# RL6842_IP_SVD register map
Vendor: Realtek
Registers are 32-bit, read-write, reset 0x0 unless marked. A register's access mark holds for its fields unless they carry their own. Offsets are from the block's base; [hi:lo] are bit positions; {n}, {i} and the like mark numbered series.

## page12
Base 0x40000000
{0x1200+0x10*i} REG_DDMA_CH{i}SA (i=0..5)
  [31:0] BIT_DDMACH{i}_SA — Source Address: the source SRAM address that DDMA will read from. This address bus support byte alignment.
{0x1204+0x10*i} REG_DDMA_CH{i}DA (i=0..5)
  [31:0] BIT_DDMACH{i}_DA — Destination Address: This address bus support byte alignment.
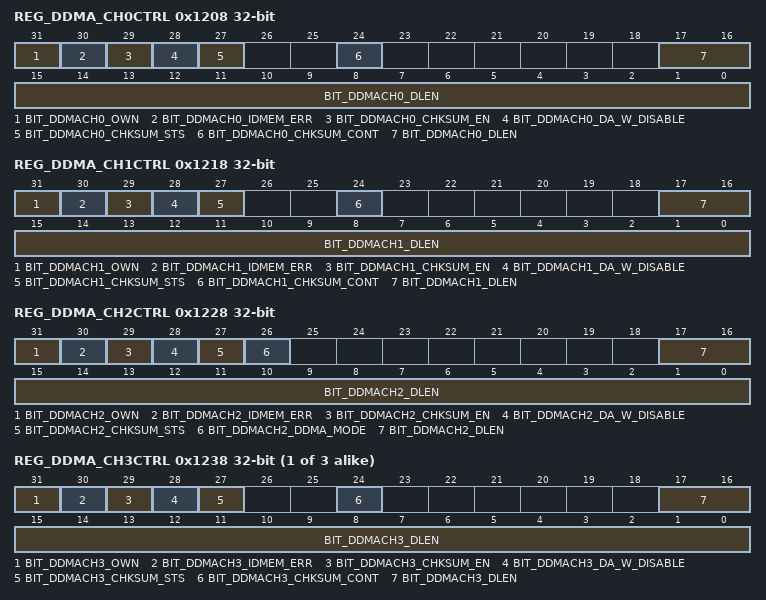
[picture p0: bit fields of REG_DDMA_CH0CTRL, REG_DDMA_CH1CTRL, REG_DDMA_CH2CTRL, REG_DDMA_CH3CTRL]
0x1208 REG_DDMA_CH0CTRL access per field
  [31] BIT_DDMACH0_OWN rw — Set '1' by firmware/driver to denote this DMA channel info is ready for DMA engine to begin DMA activity; after DMA complete, DMA engine will clear it to '0' to denote for firmware that this channel is standby again.
  [30] BIT_DDMACH0_IDMEM_ERR ro — 1: Ddma I/D MEM fail. Please check 0x80[0]=1 or DMEM protection is release 0: No error
  [29] BIT_DDMACH0_CHKSUM_EN rw — 16bits Exclusive OR checksum enable
  [28] BIT_DDMACH0_DA_W_DISABLE rw — DA write disable When DDMACH0_CHKSUM_EN=1, DDMACH0_DA_W_DISABLE = 1 means that DMA engine doesn't move pkt to destination but executes checksum only and report status to DDMACH0_CHKSUM_STS.
  [27] BIT_DDMACH0_CHKSUM_STS ro — 0: Exclusive OR checksum ok 1: Exclusive OR checksum fail
  [24] BIT_DDMACH0_CHKSUM_CONT rw — Set1, hw will continuously check sum in several ddma bursts
  [17:0] BIT_DDMACH0_DLEN rw — DMA Length: Length count served by DMA engine, unit in 1 bytes. The range is from 1 to 256K.
0x1218 REG_DDMA_CH1CTRL access per field
  [31] BIT_DDMACH1_OWN rw — Set '1' by firmware/driver to denote this DMA channel info is ready for DMA engine to begin DMA activity; after DMA complete, DMA engine will clear it to '0' to denote for firmware that this channel is standby again.
  [30] BIT_DDMACH1_IDMEM_ERR ro — 1: Ddma I/D MEM fail. Please check 0x80[0]=1 or DMEM protection is release 0: No error
  [29] BIT_DDMACH1_CHKSUM_EN rw — 16bits Exclusive OR checksum enable
  [28] BIT_DDMACH1_DA_W_DISABLE rw — DA write disable When DDMACH1_CHKSUM_EN=1, DDMACH1_DA_W_DISABLE = 1 means that DMA engine doesn't move pkt to destination but executes checksum only and report status to DDMACH1_CHKSUM_STS.
  [27] BIT_DDMACH1_CHKSUM_STS ro — 0: Exclusive OR checksum ok 1: Exclusive OR checksum fail
  [24] BIT_DDMACH1_CHKSUM_CONT rw — Set1, hw will continuously check sum in several ddma bursts
  [17:0] BIT_DDMACH1_DLEN rw — DMA Length: Length count served by DMA engine, unit in 1 bytes. The range is from 1 to 256K.
0x1228 REG_DDMA_CH2CTRL access per field
  [31] BIT_DDMACH2_OWN rw — Set '1' by firmware/driver to denote this DMA channel info is ready for DMA engine to begin DMA activity; after DMA complete, DMA engine will clear it to '0' to denote for firmware that this channel is standby again.
  [30] BIT_DDMACH2_IDMEM_ERR ro — 1: Ddma I/D MEM fail. Please check 0x80[0]=1 or DMEM protection is release 0: No error
  [29] BIT_DDMACH2_CHKSUM_EN rw — 16bits Exclusive OR checksum enable
  [28] BIT_DDMACH2_DA_W_DISABLE rw — DA write disable When DDMACH2_CHKSUM_EN=1, DDMACH2_DA_W_DISABLE = 1 means that DMA engine doesn't move pkt to destination but executes checksum only and report status to DDMACH2_CHKSUM_STS.
  [27] BIT_DDMACH2_CHKSUM_STS ro — 0: Exclusive OR checksum ok 1: Exclusive OR checksum fail
  [26] BIT_DDMACH2_DDMA_MODE rw — 0: access DMEM/IMEM using cpu idle time slot 1: access DMEM/IMEM block cpu
  [17:0] BIT_DDMACH2_DLEN rw — DMA Length: Length count served by DMA engine, unit in 1 bytes. The range is from 1 to 256K.
{0x1208+0x10*i} REG_DDMA_CH{i}CTRL access per field (i=3..5)
  [31] BIT_DDMACH{i}_OWN rw — Set '1' by firmware/driver to denote this DMA channel info is ready for DMA engine to begin DMA activity; after DMA complete, DMA engine will clear it to '0' to denote for firmware that this channel is standby again.
  [30] BIT_DDMACH{i}_IDMEM_ERR ro — 1: Ddma I/D MEM fail. Please check 0x80[0]=1 or DMEM protection is release 0: No error
  [29] BIT_DDMACH{i}_CHKSUM_EN rw — 16bits Exclusive OR checksum enable
  [28] BIT_DDMACH{i}_DA_W_DISABLE rw — DA write disable When DDMACH{i}_CHKSUM_EN=1, DDMACH{i}_DA_W_DISABLE = 1 means that DMA engine doesn't move pkt to destination but executes checksum only and report status to DDMACH{i}_CHKSUM_STS.
  [27] BIT_DDMACH{i}_CHKSUM_STS ro — 0: Exclusive OR checksum ok 1: Exclusive OR checksum fail
  [24] BIT_DDMACH{i}_CHKSUM_CONT rw — Set1, hw will continuously check sum in several ddma bursts
  [17:0] BIT_DDMACH{i}_DLEN rw — DMA Length: Length count served by DMA engine, unit in 1 bytes. The range is from 1 to 256K.
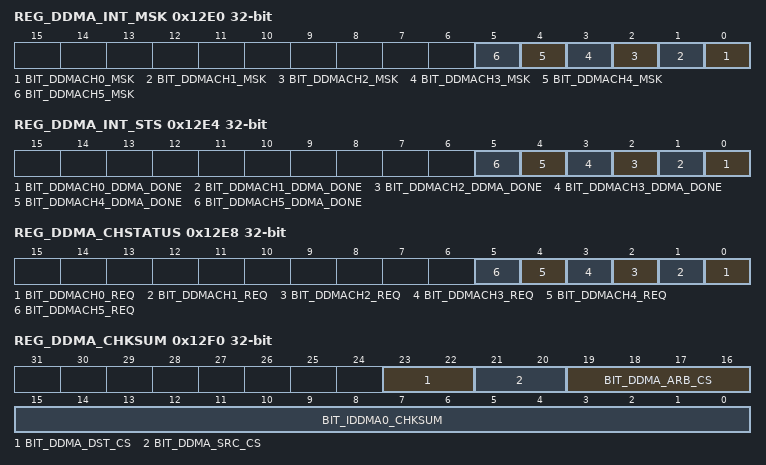
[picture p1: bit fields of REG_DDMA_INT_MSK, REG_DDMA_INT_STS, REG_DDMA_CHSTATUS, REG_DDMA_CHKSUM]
0x12E0 REG_DDMA_INT_MSK
  [n] BIT_DDMACH{n}_MSK (n=0..5) — When this bit is set, this DDMA channel will generate interrupt when the DMA done. FW may check the DDMA_CHSTATUS register to determine the DDMA status.
0x12E4 REG_DDMA_INT_STS access per field
  [n] BIT_DDMACH{n}_DDMA_DONE ro (n=0..5) — When this bit is set, this DDMA channel will generate interrupt when the DMA done.
0x12E8 REG_DDMA_CHSTATUS access per field
  [n] BIT_DDMACH{n}_REQ ro (n=0..5) — After CH{n}CTRL.OWN bit is polled, DDMA starts and asserts this bit. After the DMA transactions finish, this bit is de-asserted.
0x12F0 REG_DDMA_CHKSUM access per field
  [23:22] BIT_DDMA_DST_CS ro — ddma_dst_ctl current status
  [21:20] BIT_DDMA_SRC_CS ro — ddma_src_ctl current status
  [19:16] BIT_DDMA_ARB_CS ro — ddma_arb_ctl current status
  [15:0] BIT_IDDMA0_CHKSUM ro — Iddma0 Check sum Result
0x12F4 REG_DUMMY_P12
  [31:0] dummy
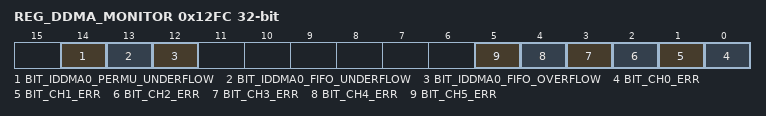
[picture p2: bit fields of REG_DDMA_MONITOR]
0x12FC REG_DDMA_MONITOR access per field
  [14] BIT_IDDMA0_PERMU_UNDERFLOW ro — IDDMA0 permu underflow,, write clear
  [13] BIT_IDDMA0_FIFO_UNDERFLOW ro — IDDMA0 fifo underflow, write clear
  [12] BIT_IDDMA0_FIFO_OVERFLOW ro — IDDMA0 fifo overflow, write clear
  [n] BIT_CH{n}_ERR ro (n=0..5) — Ch{n} is busy when it is set again, write clear
